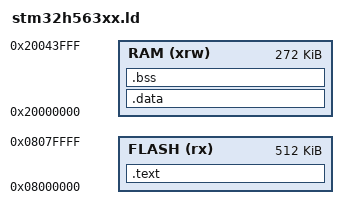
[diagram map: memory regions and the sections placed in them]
/* STM32H563xx: 512 KB Flash, 272 KB RAM (64 KB AHB SRAM + 16 KB Backup) */
MEMORY
{
    FLASH (rx)  : ORIGIN = 0x08000000, LENGTH = 512K
    RAM   (xrw) : ORIGIN = 0x20000000, LENGTH = 272K
}

ENTRY(Reset_Handler)

SECTIONS
{
    .text :
    {
        KEEP(*(.isr_vector))
        *(.text*)
        *(.rodata*)
        _etext = .;
    } > FLASH

    .data : AT(_etext)
    {
        _sdata = .;
        *(.data*)
        _edata = .;
    } > RAM

    .bss :
    {
        _sbss = .;
        *(.bss*)
        *(COMMON)
        _ebss = .;
    } > RAM

    _estack = ORIGIN(RAM) + LENGTH(RAM);
}
